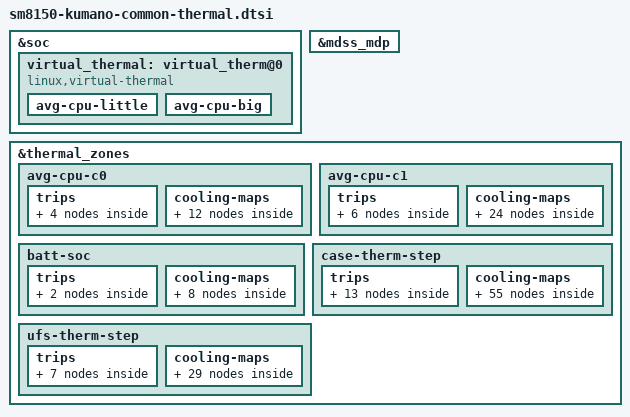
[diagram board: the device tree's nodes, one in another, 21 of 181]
/* arch/arm64/boot/dts/qcom/sm8150-kumano-common-thermal.dtsi
 *
 * This program is free software; you can redistribute it and/or modify
 * it under the terms of the GNU General Public License version 2 and
 * only version 2 as published by the Free Software Foundation.
 *
 * This program is distributed in the hope that it will be useful,
 * but WITHOUT ANY WARRANTY; without even the implied warranty of
 * MERCHANTABILITY or FITNESS FOR A PARTICULAR PURPOSE.  See the
 * GNU General Public License for more details.
 */
/*
 * Copyright (C) 2020 AngeloGioacchino Del Regno <kholk11@gmail.com>
 *
 * This program is free software; you can redistribute it and/or modify
 * it under the terms of the GNU General Public License version 2, as
 * published by the Free Software Foundation.
 */


&soc {
	virtual_thermal: virtual_therm@0 {
		compatible = "linux,virtual-thermal";
		status = "ok";
	};
};

&mdss_mdp {
	/* Backlight cooling device */
	#cooling-cells = <2>;
};

&virtual_thermal {
	avg-cpu-little {
		virt-zone-name = "avg-cpu-c0";
		thermal-sensor-names = "cpu-0-0-usr", "cpu-0-1-usr",
				  "cpu-0-2usr", "cpu-0-3-usr",
				  "cpuss-0-usr";
		aggregation-logic = <0>; /* WEIGHTED_AVG */
	};
	avg-cpu-big {
		virt-zone-name = "avg-cpu-c1";
		thermal-sensor-names = "cpu-1-0-usr", "cpu-1-1-usr",
				  "cpu-1-2-usr", "cpu-1-3-usr",
				  "cpuss-1-usr";
		aggregation-logic = <0>; /* WEIGHTED_AVG */
	};
};

&thermal_zones {
	avg-cpu-c0 {
		polling-delay-passive = <500>;
		polling-delay = <750>;
		thermal-governor = "step_wise";
		trips {
			c0_crit: c0-crit {
				temperature = <90000>;
				hysteresis = <4000>;
				type = "critical";
			};

			c0_hot: c0-hot {
				temperature = <78000>;
				hysteresis = <4000>;
				type = "hot";
			};

			c0_trip1: c0-trip1 {
				temperature = <74000>;
				hysteresis = <3000>;
				type = "passive";
				
			};

			c0_trip2: c0-trip2 {
				temperature = <70000>;
				hysteresis = <4000>;
				type = "passive";
				
			};
		};

		cooling-maps {
			/* Throttle from FMAX to 576.0MHz */
			cpu0_hot_cdev {
				trip = <&c0_hot>;
				cooling-device =
					<&CPU0 THERMAL_NO_LIMIT
						(THERMAL_MAX_LIMIT-5)>;
			};
			cpu1_hot_cdev {
				trip = <&c0_hot>;
				cooling-device =
					<&CPU1 THERMAL_NO_LIMIT
						(THERMAL_MAX_LIMIT-5)>;
			};
			cpu2_hot_cdev {
				trip = <&c0_hot>;
				cooling-device =
					<&CPU2 THERMAL_NO_LIMIT
						(THERMAL_MAX_LIMIT-5)>;
			};
			cpu3_hot_cdev {
				trip = <&c0_hot>;
				cooling-device =
					<&CPU3 THERMAL_NO_LIMIT
						(THERMAL_MAX_LIMIT-5)>;
			};
			/* Throttle from FMAX to 1113.6MHz */
			cpu0_cdev1 {
				trip = <&c0_trip1>;
				cooling-device =
					<&CPU0 THERMAL_NO_LIMIT
						(THERMAL_MAX_LIMIT-10)>;
			};
			cpu1_cdev1 {
				trip = <&c0_trip1>;
				cooling-device =
					<&CPU1 THERMAL_NO_LIMIT
						(THERMAL_MAX_LIMIT-10)>;
			};
			cpu2_cdev1 {
				trip = <&c0_trip1>;
				cooling-device =
					<&CPU2 THERMAL_NO_LIMIT
						(THERMAL_MAX_LIMIT-10)>;
			};
			cpu3_cdev1 {
				trip = <&c0_trip1>;
				cooling-device =
					<&CPU3 THERMAL_NO_LIMIT
						(THERMAL_MAX_LIMIT-10)>;
			};


			/* Throttle from FMAX to 1555.2MHz */
			cpu0_cdev2 {
				trip = <&c0_trip2>;
				cooling-device =
					<&CPU0 THERMAL_NO_LIMIT
						(THERMAL_MAX_LIMIT-15)>;
			};
			cpu1_cdev2 {
				trip = <&c0_trip2>;
				cooling-device =
					<&CPU1 THERMAL_NO_LIMIT
						(THERMAL_MAX_LIMIT-15)>;
			};
			cpu2_cdev2 {
				trip = <&c0_trip2>;
				cooling-device =
					<&CPU2 THERMAL_NO_LIMIT
						(THERMAL_MAX_LIMIT-15)>;
			};
			cpu3_cdev2 {
				trip = <&c0_trip2>;
				cooling-device =
					<&CPU3 THERMAL_NO_LIMIT
						(THERMAL_MAX_LIMIT-15)>;
			};
		};
	};

	avg-cpu-c1 {
		polling-delay-passive = <300>;
		polling-delay = <500>;
		thermal-governor = "step_wise";
		trips {
			c1_hot: c1-hot {
				temperature = <76100>;
				hysteresis = <4000>;
				type = "hot";
			};

			c1_trip0: c1-trip0 {
				temperature = <72700>;
				hysteresis = <3000>;
				type = "passive";
			};

			c1_trip1: c1-trip1 {
				temperature = <68400>;
				hysteresis = <3000>;
				type = "passive";
				
			};

			c1_trip2: c1-trip2 {
				temperature = <65300>;
				hysteresis = <3000>;
				type = "passive";
				
			};

			c1_trip3: c1-trip3 {
				temperature = <62000>;
				hysteresis = <3000>;
				type = "passive";
			};

			c1_trip4: c1-trip4 {
				temperature = <59000>;
				hysteresis = <2000>;
				type = "passive";
			};
		};

		cooling-maps {
			/* Temperature is critical: Shut down c1 */
			cpu4_crit_cdev {
				trip = <&c1_hot>;
				cooling-device =
					<&CPU4 THERMAL_MAX_LIMIT
						THERMAL_MAX_LIMIT>;
			};
			cpu5_crit_cdev {
				trip = <&c1_hot>;
				cooling-device =
					<&CPU5 THERMAL_MAX_LIMIT
						THERMAL_MAX_LIMIT>;
			};
			cpu6_crit_cdev {
				trip = <&c1_hot>;
				cooling-device =
					<&CPU6 THERMAL_MAX_LIMIT
						THERMAL_MAX_LIMIT>;
			};
			cpu7_crit_cdev {
				trip = <&c1_hot>;
				cooling-device =
					<&CPU7 THERMAL_MAX_LIMIT
						THERMAL_MAX_LIMIT>;
			};

			/* Throttle from FMAX to 1056MHz, shut down PERF-PLUS */
			cpu4_cdev4 {
				trip = <&c1_trip0>;
				cooling-device =
					<&CPU4 THERMAL_NO_LIMIT
						(THERMAL_MAX_LIMIT-4)>;
			};
			cpu5_cdev4 {
				trip = <&c1_trip0>;
				cooling-device =
					<&CPU5 THERMAL_NO_LIMIT
						(THERMAL_MAX_LIMIT-4)>;
			};
			cpu6_cdev4 {
				trip = <&c1_trip0>;
				cooling-device =
					<&CPU6 THERMAL_NO_LIMIT
						(THERMAL_MAX_LIMIT-4)>;
			};
			cpu7_cdev4 {
				trip = <&c1_trip0>;
				cooling-device =
					<&CPU7 THERMAL_MAX_LIMIT
						THERMAL_MAX_LIMIT>;
			};

			/* Throttle from FMAX to 1804.0MHz */
			cpu4_cdev5 {
				trip = <&c1_trip1>;
				cooling-device =
					<&CPU4 THERMAL_NO_LIMIT
						(THERMAL_MAX_LIMIT-11)>;
			};
			cpu5_cdev5 {
				trip = <&c1_trip1>;
				cooling-device =
					<&CPU5 THERMAL_NO_LIMIT
						(THERMAL_MAX_LIMIT-11)>;
			};
			cpu6_cdev5 {
				trip = <&c1_trip1>;
				cooling-device =
					<&CPU6 THERMAL_NO_LIMIT
						(THERMAL_MAX_LIMIT-11)>;
			};
			cpu7_cdev5 {
				trip = <&c1_trip1>;
				cooling-device =
					<&CPU7 THERMAL_NO_LIMIT
						(THERMAL_MAX_LIMIT-9)>;
			};

			/* Throttle from FMAX to 2016.0MHz */
			cpu4_cdev6 {
				trip = <&c1_trip2>;
				cooling-device =
					<&CPU4 THERMAL_NO_LIMIT
						(THERMAL_MAX_LIMIT-13)>;
			};
			cpu5_cdev6 {
				trip = <&c1_trip2>;
				cooling-device =
					<&CPU5 THERMAL_NO_LIMIT
						(THERMAL_MAX_LIMIT-13)>;
			};
			cpu6_cdev6 {
				trip = <&c1_trip2>;
				cooling-device =
					<&CPU6 THERMAL_NO_LIMIT
						(THERMAL_MAX_LIMIT-13)>;
			};
			cpu7_cdev6 {
				trip = <&c1_trip2>;
				cooling-device =
					<&CPU7 THERMAL_NO_LIMIT
						(THERMAL_MAX_LIMIT-12)>;
			};

			/* Throttle from FMAX to 2131.2MHz */
			cpu4_cdev7 {
				trip = <&c1_trip3>;
				cooling-device =
					<&CPU4 THERMAL_NO_LIMIT
						(THERMAL_MAX_LIMIT-14)>;
			};
			cpu5_cdev7 {
				trip = <&c1_trip3>;
				cooling-device =
					<&CPU5 THERMAL_NO_LIMIT
						(THERMAL_MAX_LIMIT-14)>;
			};
			cpu6_cdev7 {
				trip = <&c1_trip3>;
				cooling-device =
					<&CPU6 THERMAL_NO_LIMIT
						(THERMAL_MAX_LIMIT-14)>;
			};
			cpu7_cdev7 {
				trip = <&c1_trip3>;
				cooling-device =
					<&CPU7 THERMAL_NO_LIMIT
						(THERMAL_MAX_LIMIT-13)>;
			};

			/* Throttle from FMAX to 2227.2MHz */
			cpu4_cdev8 {
				trip = <&c1_trip4>;
				cooling-device =
					<&CPU4 THERMAL_NO_LIMIT
						(THERMAL_MAX_LIMIT-15)>;
			};
			cpu5_cdev8 {
				trip = <&c1_trip4>;
				cooling-device =
					<&CPU5 THERMAL_NO_LIMIT
						(THERMAL_MAX_LIMIT-15)>;
			};
			cpu6_cdev8 {
				trip = <&c1_trip4>;
				cooling-device =
					<&CPU6 THERMAL_NO_LIMIT
						(THERMAL_MAX_LIMIT-15)>;
			};
			cpu7_cdev8 {
				trip = <&c1_trip4>;
				cooling-device =
					<&CPU7 THERMAL_NO_LIMIT
						(THERMAL_MAX_LIMIT-14)>;
			};
		};
	};

	batt-soc {
		polling-delay-passive = <1000>;
		polling-delay = <0>;
		thermal-governor = "low_limits_cap";
		thermal-sensors = <&bcl_soc>;
		tracks-low;

		trips {
			crit_low_soc: crit-low-soc {
				temperature = <5>;
				hysteresis = <0>;
				type = "passive";
			};
			lo_soc: low-soc {
				temperature = <8>;
				hysteresis = <0>;
				type = "passive";
			};
		};

		cooling-maps {
			/* Throttle C0 from FMAX to 1478.4MHz */
			crit_soc_cpu0 {
				trip = <&crit_low_soc>;
				cooling-device =
					<&CPU0 THERMAL_NO_LIMIT
						(THERMAL_MAX_LIMIT-14)>;
			};
			crit_soc_cpu1 {
				trip = <&crit_low_soc>;
				cooling-device =
					<&CPU1 THERMAL_NO_LIMIT
						(THERMAL_MAX_LIMIT-14)>;
			};
			crit_soc_cpu2 {
				trip = <&crit_low_soc>;
				cooling-device =
					<&CPU2 THERMAL_NO_LIMIT
						(THERMAL_MAX_LIMIT-14)>;
			};
			crit_soc_cpu3 {
				trip = <&crit_low_soc>;
				cooling-device =
					<&CPU3 THERMAL_NO_LIMIT
						(THERMAL_MAX_LIMIT-14)>;
			};

			/* Shut down C1 */
			soc_cpu4 {
				trip = <&lo_soc>;
				cooling-device =
					<&CPU4 THERMAL_MAX_LIMIT
						THERMAL_MAX_LIMIT>;
			};
			soc_cpu5 {
				trip = <&lo_soc>;
				cooling-device =
					<&CPU5 THERMAL_MAX_LIMIT
						THERMAL_MAX_LIMIT>;
			};
			soc_cpu6 {
				trip = <&lo_soc>;
				cooling-device =
					<&CPU6 THERMAL_MAX_LIMIT
						THERMAL_MAX_LIMIT>;
			};
			soc_cpu7 {
				trip = <&lo_soc>;
				cooling-device =
					<&CPU7 THERMAL_MAX_LIMIT
						THERMAL_MAX_LIMIT>;
			};
		};
	};

	case-therm-step {
		polling-delay-passive = <2000>;
		polling-delay = <0>;
		thermal-sensors = <&pm8150b_adc_tm ADC_AMUX_THM2_PU2>;
		thermal-governor = "step_wise";

		trips {
			skin_critical: skin-crit {
				temperature = <73500>;
				hysteresis = <2000>;
				type = "critical";
			};

			cpu_ct_trip0: cpu-ct-trip0 {
				temperature = <63000>;
				hysteresis = <3000>;
				type = "passive";
			};
			cpu_ct_trip1: cpu-ct-trip1 {
				temperature = <55700>;
				hysteresis = <1000>;
				type = "passive";
			};
			cpu_ct_trip2: cpu-ct-trip2 {
				temperature = <54700>;
				hysteresis = <1200>;
				type = "passive";
			};
			cpu_ct_trip3: cpu-ct-trip3 {
				temperature = <52500>;
				hysteresis = <1100>;
				type = "passive";
			};
			cpu_ct_trip4: cpu-ct-trip4 {
				temperature = <51400>;
				hysteresis = <1200>;
				type = "passive";
			};
			cpu_ct_trip5: cpu-ct-trip5 {
				temperature = <50200>;
				hysteresis = <300>;
				type = "passive";
			};
			cpu_ct_trip6: cpu-ct-trip6 {
				temperature = <48600>;
				hysteresis = <1200>;
				type = "passive";
			};
			cpu_ct_trip7: cpu-ct-trip7 {
				temperature = <47700>;
				hysteresis = <2700>;
				type = "passive";
			};

			charger_trip0: cpu-ct-trip8 {
				temperature = <45000>;
				hysteresis = <3000>;
				type = "passive";
			};

			modem_case_trip0: modem-trip0 {
				temperature = <47000>;
				hysteresis = <2000>;
				type = "passive";
			};
			modem_case_trip1: modem-trip1 {
				temperature = <51000>;
				hysteresis = <3000>;
				type = "passive";
			};
			modem_case_trip2: modem-trip2 {
				temperature = <55000>;
				hysteresis = <4000>;
				type = "passive";
			};
		};

		cooling-maps {
			/* Throttle from FMAX to 576MHz */
			skin0_cpu0 {
				trip = <&cpu_ct_trip0>;
				cooling-device = <&CPU0 THERMAL_NO_LIMIT
							(THERMAL_MAX_LIMIT-4)>;
			};
			skin0_cpu1 {
				trip = <&cpu_ct_trip0>;
				cooling-device = <&CPU1 THERMAL_NO_LIMIT
							(THERMAL_MAX_LIMIT-4)>;
			};
			skin0_cpu2 {
				trip = <&cpu_ct_trip0>;
				cooling-device = <&CPU2 THERMAL_NO_LIMIT
							(THERMAL_MAX_LIMIT-4)>;
			};
			skin0_cpu3 {
				trip = <&cpu_ct_trip0>;
				cooling-device = <&CPU3 THERMAL_NO_LIMIT
							(THERMAL_MAX_LIMIT-4)>;
			};
			/* Reaching critical: shutdown C1 */
			skin0_cpu4 {
				trip = <&cpu_ct_trip0>;
				cooling-device = <&CPU4 THERMAL_NO_LIMIT
							THERMAL_MAX_LIMIT>;
			};
			skin0_cpu5 {
				trip = <&cpu_ct_trip0>;
				cooling-device = <&CPU5 THERMAL_NO_LIMIT
							THERMAL_MAX_LIMIT>;
			};
			skin0_cpu6 {
				trip = <&cpu_ct_trip0>;
				cooling-device = <&CPU6 THERMAL_NO_LIMIT
							THERMAL_MAX_LIMIT>;
			};
			skin0_cpu7 {
				trip = <&cpu_ct_trip0>;
				cooling-device = <&CPU7 THERMAL_NO_LIMIT
							THERMAL_MAX_LIMIT>;
			};

			/* Throttle from FMAX to 940-940.8MHz */
			skin1_cpu0 {
				trip = <&cpu_ct_trip1>;
				cooling-device = <&CPU0 THERMAL_NO_LIMIT
							(THERMAL_MAX_LIMIT-8)>;
			};
			skin1_cpu1 {
				trip = <&cpu_ct_trip1>;
				cooling-device = <&CPU1 THERMAL_NO_LIMIT
							(THERMAL_MAX_LIMIT-8)>;
			};
			skin1_cpu2 {
				trip = <&cpu_ct_trip1>;
				cooling-device = <&CPU2 THERMAL_NO_LIMIT
							(THERMAL_MAX_LIMIT-8)>;
			};
			skin1_cpu3 {
				trip = <&cpu_ct_trip1>;
				cooling-device = <&CPU3 THERMAL_NO_LIMIT
							(THERMAL_MAX_LIMIT-8)>;
			};
			skin1_cpu4 {
				trip = <&cpu_ct_trip1>;
				cooling-device = <&CPU4 THERMAL_NO_LIMIT
							(THERMAL_MAX_LIMIT-3)>;
			};
			skin1_cpu5 {
				trip = <&cpu_ct_trip1>;
				cooling-device = <&CPU5 THERMAL_NO_LIMIT
							(THERMAL_MAX_LIMIT-3)>;
			};
			skin1_cpu6 {
				trip = <&cpu_ct_trip1>;
				cooling-device = <&CPU6 THERMAL_NO_LIMIT
							(THERMAL_MAX_LIMIT-3)>;
			};
			skin1_cpu7 {
				trip = <&cpu_ct_trip1>;
				cooling-device = <&CPU7 THERMAL_NO_LIMIT
							(THERMAL_MAX_LIMIT-2)>;
			};

			/* Throttle from FMAX to 1632.0-1497.6MHz */
			skin2_cpu0 {
				trip = <&cpu_ct_trip2>;
				cooling-device = <&CPU0 THERMAL_NO_LIMIT
							(THERMAL_MAX_LIMIT-16)>;
			};
			skin2_cpu1 {
				trip = <&cpu_ct_trip2>;
				cooling-device = <&CPU1 THERMAL_NO_LIMIT
							(THERMAL_MAX_LIMIT-16)>;
			};
			skin2_cpu2 {
				trip = <&cpu_ct_trip2>;
				cooling-device = <&CPU2 THERMAL_NO_LIMIT
							(THERMAL_MAX_LIMIT-16)>;
			};
			skin2_cpu3 {
				trip = <&cpu_ct_trip2>;
				cooling-device = <&CPU3 THERMAL_NO_LIMIT
							(THERMAL_MAX_LIMIT-16)>;
			};
			skin2_cpu4 {
				trip = <&cpu_ct_trip2>;
				cooling-device = <&CPU4 THERMAL_NO_LIMIT
							(THERMAL_MAX_LIMIT-8)>;
			};
			skin2_cpu5 {
				trip = <&cpu_ct_trip2>;
				cooling-device = <&CPU5 THERMAL_NO_LIMIT
							(THERMAL_MAX_LIMIT-8)>;
			};
			skin2_cpu6 {
				trip = <&cpu_ct_trip2>;
				cooling-device = <&CPU6 THERMAL_NO_LIMIT
							(THERMAL_MAX_LIMIT-8)>;
			};
			skin2_cpu7 {
				trip = <&cpu_ct_trip2>;
				cooling-device = <&CPU7 THERMAL_NO_LIMIT
							(THERMAL_MAX_LIMIT-7)>;
			};

			/* Throttle from FMAX to 1708.8-1612.8MHz */
			skin3_cpu0 {
				trip = <&cpu_ct_trip3>;
				cooling-device = <&CPU0 THERMAL_NO_LIMIT
							(THERMAL_MAX_LIMIT-17)>;
			};
			skin3_cpu1 {
				trip = <&cpu_ct_trip3>;
				cooling-device = <&CPU1 THERMAL_NO_LIMIT
							(THERMAL_MAX_LIMIT-17)>;
			};
			skin3_cpu2 {
				trip = <&cpu_ct_trip3>;
				cooling-device = <&CPU2 THERMAL_NO_LIMIT
							(THERMAL_MAX_LIMIT-17)>;
			};
			skin3_cpu3 {
				trip = <&cpu_ct_trip3>;
				cooling-device = <&CPU3 THERMAL_NO_LIMIT
							(THERMAL_MAX_LIMIT-17)>;
			};
			skin3_cpu4 {
				trip = <&cpu_ct_trip3>;
				cooling-device = <&CPU4 THERMAL_NO_LIMIT
							(THERMAL_MAX_LIMIT-9)>;
			};
			skin3_cpu5 {
				trip = <&cpu_ct_trip3>;
				cooling-device = <&CPU5 THERMAL_NO_LIMIT
							(THERMAL_MAX_LIMIT-9)>;
			};
			skin3_cpu6 {
				trip = <&cpu_ct_trip3>;
				cooling-device = <&CPU6 THERMAL_NO_LIMIT
							(THERMAL_MAX_LIMIT-9)>;
			};
			skin3_cpu7 {
				trip = <&cpu_ct_trip3>;
				cooling-device = <&CPU7 THERMAL_NO_LIMIT
							(THERMAL_MAX_LIMIT-8)>;
			};


			/* Throttle C1 only from FMAX to 2227.2MHz */
			skin4_cpu4 {
				trip = <&cpu_ct_trip4>;
				cooling-device = <&CPU4 THERMAL_NO_LIMIT
							(THERMAL_MAX_LIMIT-15)>;
			};
			skin4_cpu5 {
				trip = <&cpu_ct_trip4>;
				cooling-device = <&CPU5 THERMAL_NO_LIMIT
							(THERMAL_MAX_LIMIT-15)>;
			};
			skin4_cpu6 {
				trip = <&cpu_ct_trip4>;
				cooling-device = <&CPU6 THERMAL_NO_LIMIT
							(THERMAL_MAX_LIMIT-15)>;
			};
			skin4_cpu7 {
				trip = <&cpu_ct_trip4>;
				cooling-device = <&CPU7 THERMAL_NO_LIMIT
							(THERMAL_MAX_LIMIT-14)>;
			};

			/* Throttle C1 only from FMAX to 2419.2MHz */
			skin5_cpu4 {
				trip = <&cpu_ct_trip5>;
				cooling-device = <&CPU4 THERMAL_NO_LIMIT
							(THERMAL_MAX_LIMIT-17)>;
			};
			skin5_cpu5 {
				trip = <&cpu_ct_trip5>;
				cooling-device = <&CPU5 THERMAL_NO_LIMIT
							(THERMAL_MAX_LIMIT-17)>;
			};
			skin5_cpu6 {
				trip = <&cpu_ct_trip5>;
				cooling-device = <&CPU6 THERMAL_NO_LIMIT
							(THERMAL_MAX_LIMIT-17)>;
			};
			skin5_cpu7 {
				trip = <&cpu_ct_trip5>;
				cooling-device = <&CPU7 THERMAL_NO_LIMIT
							(THERMAL_MAX_LIMIT-16)>;
			};

			/* Throttle PERF-PLUS CPU (on C1) only from FMAX to 2649.6MHz */
			skin6_cpu7 {
				trip = <&cpu_ct_trip6>;
				cooling-device = <&CPU7 THERMAL_NO_LIMIT
							(THERMAL_MAX_LIMIT-18)>;
			};

			/* Throttle from FMAX to 257MHz */
			skin0_gpu {
				trip = <&cpu_ct_trip1>;
				cooling-device = <&msm_gpu THERMAL_NO_LIMIT
							   (THERMAL_MAX_LIMIT-1)>;
			};

			/* Battery charging current limit */
			charger_lvl1 {
				trip = <&cpu_ct_trip0>;
				cooling-device = <&pm8150b_charger 13 13>;
			};
			charger_lvl2 {
				trip = <&cpu_ct_trip1>;
				cooling-device = <&pm8150b_charger 12 12>;
			};
			charger_lvl3 {
				trip = <&cpu_ct_trip2>;
				cooling-device = <&pm8150b_charger 11 11>;
			};
			charger_lvl4 {
				trip = <&cpu_ct_trip3>;
				cooling-device = <&pm8150b_charger 10 10>;
			};
			charger_lvl5 {
				trip = <&cpu_ct_trip4>;
				cooling-device = <&pm8150b_charger 9 9>;
			};
			charger_lvl6 {
				trip = <&cpu_ct_trip5>;
				cooling-device = <&pm8150b_charger 8 8>;
			};
			charger_lvl7 {
				trip = <&cpu_ct_trip6>;
				cooling-device = <&pm8150b_charger 5 5>;
			};
			charger_lvl8 {
				trip = <&cpu_ct_trip7>;
				cooling-device = <&pm8150b_charger 2 2>;
			};

			/* Modem PA power limit */
			modem_lvl1 {
				trip = <&modem_case_trip1>;
				cooling-device = <&modem0_pa 1 1>;
			};
			modem_lvl2 {
				trip = <&modem_case_trip2>;
				cooling-device = <&modem0_pa 2 2>;
			};

			/* Modem proc limit */
			modem_proc_lvl1 {
				trip = <&modem_case_trip0>;
				cooling-device = <&modem0_proc 1 1>;
			};
			modem_proc_lvl2 {
				trip = <&modem_case_trip2>;
				cooling-device = <&modem0_proc 3 3>;
			};

			/* Backlight limits (for range 0-4095) */
			bl_lvl1 {
				trip = <&cpu_ct_trip4>;
				cooling-device = <&mdss_mdp 1 3610>;
			};
		};
	};

	ufs-therm-step {
		polling-delay-passive = <1000>;
		polling-delay = <0>;
		thermal-sensors = <&pm8150b_adc_tm ADC_AMUX_THM2_PU2>;
		thermal-governor = "step_wise";

		trips {
			ufs_critical: ufs-crit {
				temperature = <78000>;
				hysteresis = <1000>;
				type = "critical";
			};

			ufs_trip_hot: ufs-hot {
				temperature = <69100>;
				hysteresis = <4000>;
				type = "passive";
			};

			ufs_trip0: ufs-trip0 {
				temperature = <64500>;
				hysteresis = <4000>;
				type = "passive";
			};
			ufs_trip1: ufs-trip1 {
				temperature = <55100>;
				hysteresis = <1000>;
				type = "passive";
			};
			ufs_trip2: ufs-trip2 {
				temperature = <54300>;
				hysteresis = <1200>;
				type = "passive";
			};
			ufs_trip3: ufs-trip3 {
				temperature = <52900>;
				hysteresis = <1100>;
				type = "passive";
			};
			ufs_trip4: ufs-trip4 {
				temperature = <50800>;
				hysteresis = <1200>;
				type = "passive";
			};
		};

		cooling-maps {
			/* Throttle from FMAX to 576MHz */
			ufs_mit_0_cpu0 {
				trip = <&ufs_trip0>;
				cooling-device = <&CPU0 THERMAL_NO_LIMIT
							(THERMAL_MAX_LIMIT-4)>;
			};
			ufs_mit_0_cpu1 {
				trip = <&ufs_trip0>;
				cooling-device = <&CPU1 THERMAL_NO_LIMIT
							(THERMAL_MAX_LIMIT-4)>;
			};
			ufs_mit_0_cpu2 {
				trip = <&ufs_trip0>;
				cooling-device = <&CPU2 THERMAL_NO_LIMIT
							(THERMAL_MAX_LIMIT-4)>;
			};
			ufs_mit_0_cpu3 {
				trip = <&ufs_trip0>;
				cooling-device = <&CPU3 THERMAL_NO_LIMIT
							(THERMAL_MAX_LIMIT-4)>;
			};
			/* Reaching critical: shutdown C1 */
			ufs_mit_0_cpu4 {
				trip = <&ufs_trip0>;
				cooling-device = <&CPU4 THERMAL_NO_LIMIT
							THERMAL_MAX_LIMIT>;
			};
			ufs_mit_0_cpu5 {
				trip = <&ufs_trip0>;
				cooling-device = <&CPU5 THERMAL_NO_LIMIT
							THERMAL_MAX_LIMIT>;
			};
			ufs_mit_0_cpu6 {
				trip = <&ufs_trip0>;
				cooling-device = <&CPU6 THERMAL_NO_LIMIT
							THERMAL_MAX_LIMIT>;
			};
			ufs_mit_0_cpu7 {
				trip = <&ufs_trip0>;
				cooling-device = <&CPU7 THERMAL_NO_LIMIT
							THERMAL_MAX_LIMIT>;
			};

			/* Throttle from FMAX to 1632.0-1804.8MHz */
			ufs_mit_1_cpu0 {
				trip = <&ufs_trip1>;
				cooling-device = <&CPU0 THERMAL_NO_LIMIT
							(THERMAL_MAX_LIMIT-15)>;
			};
			ufs_mit_1_cpu1 {
				trip = <&ufs_trip1>;
				cooling-device = <&CPU1 THERMAL_NO_LIMIT
							(THERMAL_MAX_LIMIT-15)>;
			};
			ufs_mit_1_cpu2 {
				trip = <&ufs_trip1>;
				cooling-device = <&CPU2 THERMAL_NO_LIMIT
							(THERMAL_MAX_LIMIT-15)>;
			};
			ufs_mit_1_cpu3 {
				trip = <&ufs_trip1>;
				cooling-device = <&CPU3 THERMAL_NO_LIMIT
							(THERMAL_MAX_LIMIT-15)>;
			};
			ufs_mit_1_cpu4 {
				trip = <&ufs_trip1>;
				cooling-device = <&CPU4 THERMAL_NO_LIMIT
							(THERMAL_MAX_LIMIT-11)>;
			};
			ufs_mit_1_cpu5 {
				trip = <&ufs_trip1>;
				cooling-device = <&CPU5 THERMAL_NO_LIMIT
							(THERMAL_MAX_LIMIT-11)>;
			};
			ufs_mit_1_cpu6 {
				trip = <&ufs_trip1>;
				cooling-device = <&CPU6 THERMAL_NO_LIMIT
							(THERMAL_MAX_LIMIT-11)>;
			};
			ufs_mit_1_cpu7 {
				trip = <&ufs_trip1>;
				cooling-device = <&CPU7 THERMAL_NO_LIMIT
							(THERMAL_MAX_LIMIT-10)>;
			};

			/* Throttle C1 only from FMAX to 2016.0MHz */
			ufs_mit_2_cpu4 {
				trip = <&ufs_trip2>;
				cooling-device = <&CPU4 THERMAL_NO_LIMIT
							(THERMAL_MAX_LIMIT-13)>;
			};
			ufs_mit_2_cpu5 {
				trip = <&ufs_trip2>;
				cooling-device = <&CPU5 THERMAL_NO_LIMIT
							(THERMAL_MAX_LIMIT-13)>;
			};
			ufs_mit_2_cpu6 {
				trip = <&ufs_trip2>;
				cooling-device = <&CPU6 THERMAL_NO_LIMIT
							(THERMAL_MAX_LIMIT-13)>;
			};
			ufs_mit_2_cpu7 {
				trip = <&ufs_trip2>;
				cooling-device = <&CPU7 THERMAL_NO_LIMIT
							(THERMAL_MAX_LIMIT-12)>;
			};

			/* Throttle PERFPLUS from FMAX to 2649.6MHz */
			ufs_mit_3_cpu7 {
				trip = <&ufs_trip3>;
				cooling-device = <&CPU7 THERMAL_NO_LIMIT
							(THERMAL_MAX_LIMIT-18)>;
			};


			/* Throttle PERFPLUS from FMAX to 2754.6MHz */
			ufs_mit_4_cpu7 {
				trip = <&ufs_trip4>;
				cooling-device = <&CPU7 THERMAL_NO_LIMIT
							(THERMAL_MAX_LIMIT-19)>;
			};

			/* Battery charging current limit */
			charger_ufs_lvl1 {
				trip = <&ufs_trip0>;
				cooling-device = <&pm8150b_charger 13 13>;
			};
			charger_ufs_lvl2 {
				trip = <&ufs_trip1>;
				cooling-device = <&pm8150b_charger 12 12>;
			};
			charger_ufs_lvl3 {
				trip = <&ufs_trip2>;
				cooling-device = <&pm8150b_charger 11 11>;
			};
			charger_ufs_lvl4 {
				trip = <&ufs_trip3>;
				cooling-device = <&pm8150b_charger 10 10>;
			};
			charger_ufs_lvl5 {
				trip = <&ufs_trip4>;
				cooling-device = <&pm8150b_charger 9 9>;
			};

			/* Modem proc limit for UFS overheat */
			modem_proc_lvl1 {
				trip = <&ufs_trip0>;
				cooling-device = <&modem0_proc 1 1>;
			};

			/* Modem PA power limit */
			modem_lvl1 {
				trip = <&ufs_trip_hot>;
				cooling-device = <&modem0_pa 1 1>;
			};
		};
	};
};
